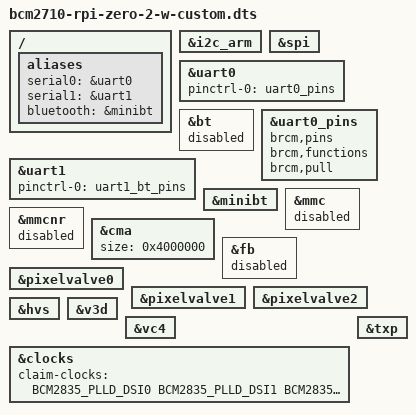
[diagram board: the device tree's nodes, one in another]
// SPDX-License-Identifier: GPL-2.0
#include "arm/broadcom/bcm2710-rpi-zero-2-w.dts"

#include <dt-bindings/gpio/gpio.h>
#include <dt-bindings/clock/bcm2835.h>

// i2c_arm=on
&i2c_arm {
	status = "okay";
};

// spi=on
&spi {
	status = "okay";
};

// miniuart-bt
&uart0 {
	pinctrl-names = "default";
	pinctrl-0 = <&uart0_pins>;
	status = "okay";
};

&bt {
	status = "disabled";
};

&uart1 {
	pinctrl-names = "default";
	pinctrl-0 = <&uart1_bt_pins>;
	status = "okay";
};

&uart0_pins {
	brcm,pins;
	brcm,functions;
	brcm,pull;
};

&minibt {
	status = "okay";
};

/ {
	aliases {
		serial0 = &uart0;
		serial1 = &uart1;
		bluetooth = &minibt;
	};
};

// disable-wifi
&mmc {
	status = "disabled";
};

&mmcnr {
	status = "disabled";
};

// vc4-kms-v3d,cma-64,noaudio,nohdmi
&cma {
	size = <0x4000000>;
};

&fb {
	status = "disabled";
};

&pixelvalve0 {
	status = "okay";
};

&pixelvalve1 {
	status = "okay";
};

&pixelvalve2 {
	status = "okay";
};

&hvs {
	status = "okay";
};

&v3d {
	status = "okay";
};

&vc4 {
	status = "okay";
};

&clocks {
	claim-clocks = <
		BCM2835_PLLD_DSI0
		BCM2835_PLLD_DSI1
		BCM2835_PLLH_AUX
		BCM2835_PLLH_PIX
	>;
};

&txp {
	status = "okay";
};
